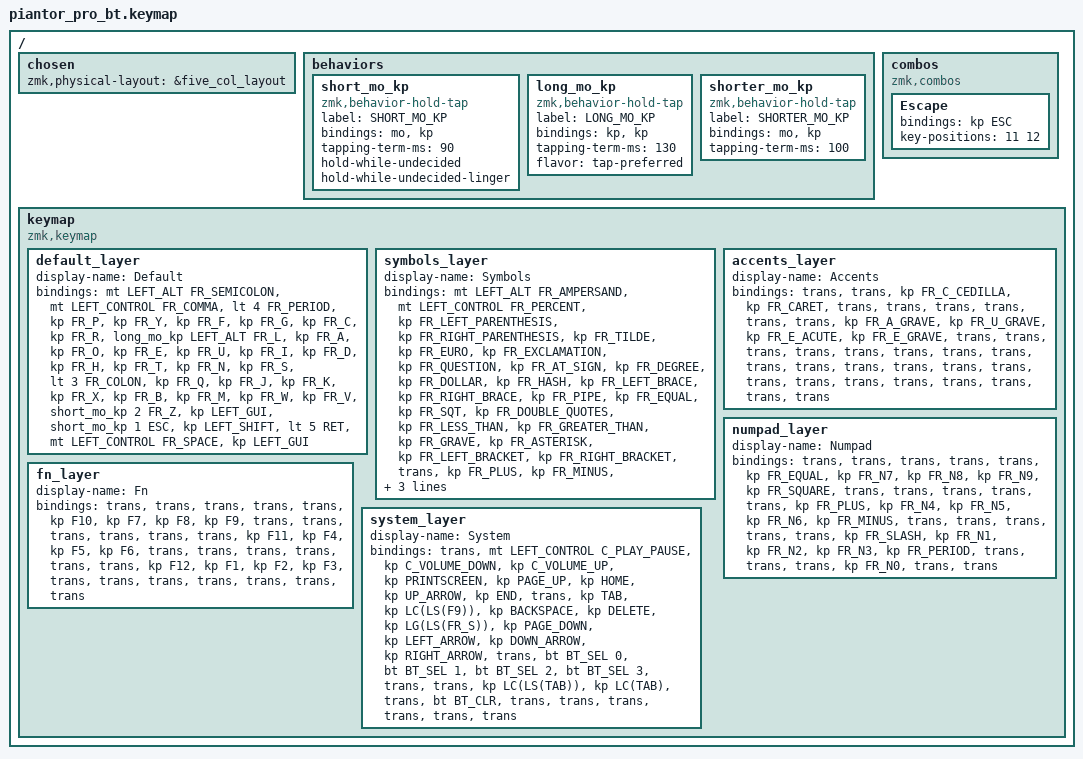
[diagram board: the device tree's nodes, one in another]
/*
 * Copyright (c) 2020 The ZMK Contributors
 *
 * SPDX-License-Identifier: MIT
 */

#include <behaviors.dtsi>
#include <dt-bindings/zmk/bt.h>
#include <dt-bindings/zmk/keys.h>
#include "zmk-helpers/helper.h"
#include "keys_fr.h"

/ {
    chosen { zmk,physical-layout = &five_col_layout; };
};

/ {
    behaviors {
        short_mo_kp: short_mo_kp {
            compatible = "zmk,behavior-hold-tap";
            label = "SHORT_MO_KP";
            bindings = <&mo>, <&kp>;

            #binding-cells = <2>;
            tapping-term-ms = <90>;
            hold-while-undecided;
            hold-while-undecided-linger;
        };

        long_mo_kp: long_mo_kp {
            compatible = "zmk,behavior-hold-tap";
            label = "LONG_MO_KP";
            bindings = <&kp>, <&kp>;

            #binding-cells = <2>;
            tapping-term-ms = <130>;
            flavor = "tap-preferred";
        };

        shorter_mo_kp: shorter_mo_kp {
            compatible = "zmk,behavior-hold-tap";
            label = "SHORTER_MO_KP";
            bindings = <&mo>, <&kp>;

            #binding-cells = <2>;
            tapping-term-ms = <100>;
        };
    };

    combos {
        compatible = "zmk,combos";

        Escape {
            bindings = <&kp ESC>;
            key-positions = <11 12>;
        };
    };

    keymap {
        compatible = "zmk,keymap";

        default_layer {
            display-name = "Default";

            // --------------------------------------------------------------
            // |  Q  |  W  |  E  |  R  |  T  |  Y  |  U   |  I  |  O  |  P  |
            // |  A  |  S  |  D  |  F  |  G  |  H  |  J   |  K  |  L  |  ;  |
            // |  Z  |  X  |  C  |  V  |  B  |  N  |  M   |  ,  |  .  |  /  |
            //                    | GUI | LWR | SPC | ENT | RSE  | ALT |

            bindings = <
  &mt LEFT_ALT FR_SEMICOLON  &mt LEFT_CONTROL FR_COMMA  &lt 4 FR_PERIOD  &kp FR_P  &kp FR_Y  &kp FR_F  &kp FR_G  &kp FR_C  &kp FR_R  &long_mo_kp LEFT_ALT FR_L      &kp FR_A  &kp FR_O  &kp FR_E  &kp FR_U  &kp FR_I  &kp FR_D  &kp FR_H  &kp FR_T  &kp FR_N  &kp FR_S      &lt 3 FR_COLON  &kp FR_Q  &kp FR_J  &kp FR_K  &kp FR_X  &kp FR_B  &kp FR_M  &kp FR_W  &kp FR_V  &short_mo_kp 2 FR_Z    &kp LEFT_GUI  &short_mo_kp 1 ESC  &kp LEFT_SHIFT  &lt 5 RET  &mt LEFT_CONTROL FR_SPACE  &kp LEFT_GUI
            >;
        };

        symbols_layer {
            display-name = "Symbols";

            // ---------------------------------------------------------------
            // |  1  |  2  |  3  |  4  |  5    |  6  |  7  |  8  |  9  |  0  |
            // | BT1 | BT2 | BT3 | BT4 | BT5   | LFT | DWN |  UP | RGT |     |
            // | BTCR| RGB | RST | BOOT| Unlock|     |     |     |     |     |
            //                    | GUI |     | SPC   | ENT |     | ALT |

            bindings = <
  &mt LEFT_ALT FR_AMPERSAND  &mt LEFT_CONTROL FR_PERCENT  &kp FR_LEFT_PARENTHESIS  &kp FR_RIGHT_PARENTHESIS  &kp FR_TILDE  &kp FR_EURO  &kp FR_EXCLAMATION  &kp FR_QUESTION  &kp FR_AT_SIGN  &kp FR_DEGREE      &kp FR_DOLLAR  &kp FR_HASH  &kp FR_LEFT_BRACE  &kp FR_RIGHT_BRACE  &kp FR_PIPE  &kp FR_EQUAL  &kp FR_SQT  &kp FR_DOUBLE_QUOTES  &kp FR_LESS_THAN  &kp FR_GREATER_THAN      &kp FR_GRAVE  &kp FR_ASTERISK  &kp FR_LEFT_BRACKET  &kp FR_RIGHT_BRACKET  &trans  &kp FR_PLUS  &kp FR_MINUS  &kp FR_UNDERSCORE  &kp FR_SLASH  &kp FR_BACKSLASH    &trans  &trans  &trans  &trans  &trans  &trans
            >;
        };

        accents_layer {
            display-name = "Accents";

            // -------------------------------------------------------------
            // |  !  |  @  |  #  |  $  |  %  |  ^  |  &  |  *  |  (  |  )  |
            // |     |     |     |     |     |  -  |  =  |  [  |  ]  |  \  |
            // |     |     |     |     |     |  _  |  +  |  {  |  }  | "|" |
            //                    | GUI |     | SPC | ENT |     | ALT |

            bindings = <
  &trans  &trans  &kp FR_C_CEDILLA  &kp FR_CARET  &trans  &trans  &trans  &trans  &trans  &trans      &kp FR_A_GRAVE  &kp FR_U_GRAVE  &kp FR_E_ACUTE  &kp FR_E_GRAVE  &trans  &trans  &trans  &trans  &trans  &trans      &trans  &trans  &trans  &trans  &trans  &trans  &trans  &trans  &trans  &trans    &trans  &trans  &trans  &trans  &trans  &trans
            >;
        };

        numpad_layer {
            display-name = "Numpad";
            bindings = <
  &trans  &trans  &trans  &trans  &trans  &kp FR_EQUAL  &kp FR_N7  &kp FR_N8  &kp FR_N9  &kp FR_SQUARE      &trans  &trans  &trans  &trans  &trans  &kp FR_PLUS  &kp FR_N4  &kp FR_N5  &kp FR_N6  &kp FR_MINUS      &trans  &trans  &trans  &trans  &trans  &kp FR_SLASH  &kp FR_N1  &kp FR_N2  &kp FR_N3  &kp FR_PERIOD    &trans  &trans  &trans  &kp FR_N0  &trans  &trans
            >;
        };

        fn_layer {
            display-name = "Fn";
            bindings = <
  &trans  &trans  &trans  &trans  &trans  &kp F10  &kp F7  &kp F8  &kp F9  &trans      &trans  &trans  &trans  &trans  &trans  &kp F11  &kp F4  &kp F5  &kp F6  &trans      &trans  &trans  &trans  &trans  &trans  &kp F12  &kp F1  &kp F2  &kp F3  &trans    &trans  &trans  &trans  &trans  &trans  &trans
            >;
        };

        system_layer {
            display-name = "System";
            bindings = <
  &trans  &mt LEFT_CONTROL C_PLAY_PAUSE  &kp C_VOLUME_DOWN  &kp C_VOLUME_UP  &kp PRINTSCREEN  &kp PAGE_UP  &kp HOME  &kp UP_ARROW  &kp END  &trans      &kp TAB  &kp LC(LS(F9))  &kp BACKSPACE  &kp DELETE  &kp LG(LS(FR_S))  &kp PAGE_DOWN  &kp LEFT_ARROW  &kp DOWN_ARROW  &kp RIGHT_ARROW  &trans      &bt BT_SEL 0  &bt BT_SEL 1  &bt BT_SEL 2  &bt BT_SEL 3  &trans  &trans  &kp LC(LS(TAB))  &kp LC(TAB)  &trans  &bt BT_CLR    &trans  &trans  &trans  &trans  &trans  &trans
            >;
        };
    };
};
